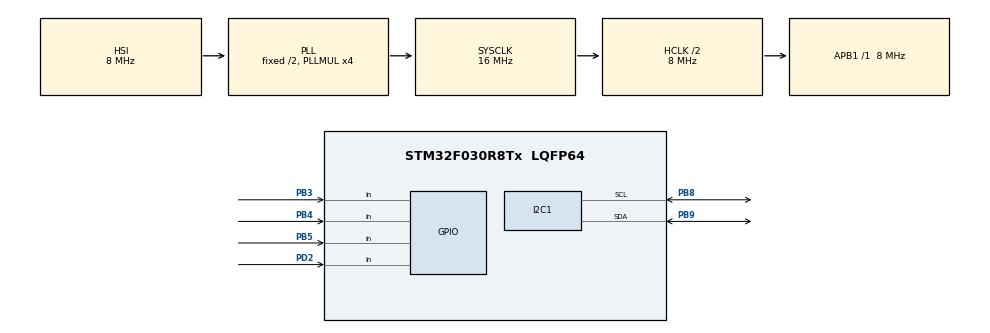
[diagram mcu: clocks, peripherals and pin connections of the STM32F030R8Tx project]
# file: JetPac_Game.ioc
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FREERTOS.Tasks01=defaultTask,0,128,StartDefaultTask,Default,NULL
Mcu.Family=STM32F0
Mcu.Name=STM32F030R8Tx
Mcu.Package=LQFP64
NVIC.TIM1_BRK_UP_TRG_COM_IRQn=true\:0\:0\:false\:false\:true\:false\:false
NVIC.TimeBase=TIM1_BRK_UP_TRG_COM_IRQn
NVIC.TimeBaseIP=TIM1
PB3.GPIO_Mode=GPIO_MODE_INPUT
PB3.GPIO_PuPd=GPIO_PULLUP
PB3.Signal=GPIO_Input
PB4.GPIO_Mode=GPIO_MODE_INPUT
PB4.GPIO_PuPd=GPIO_PULLUP
PB4.Signal=GPIO_Input
PB5.GPIO_Mode=GPIO_MODE_INPUT
PB5.GPIO_PuPd=GPIO_PULLUP
PB5.Signal=GPIO_Input
PB8.Mode=I2C
PB8.Signal=I2C1_SCL
PB9.Mode=I2C
PB9.Signal=I2C1_SDA
PD2.Signal=GPIO_Input
ProjectManager.HeapSize=0x200
ProjectManager.StackSize=0x400
ProjectManager.TargetToolchain=SW4STM32
RCC.AHBCLKDivider=RCC_SYSCLK_DIV2
RCC.AHBFreq_Value=8000000
RCC.APB1Freq_Value=8000000
RCC.APB1TimFreq_Value=8000000
RCC.HCLKFreq_Value=8000000
RCC.PLLMUL=RCC_PLL_MUL4
RCC.SYSCLKFreq_VALUE=16000000
RCC.SYSCLKSource=RCC_SYSCLKSOURCE_PLLCLK
VP_FREERTOS_VS_ENABLE.Mode=Enabled
VP_SYS_VS_tim1.Mode=TIM1
VP_TIM14_VS_ClockSourceINT.Mode=Enable_Timer
VP_TIM6_VS_ClockSourceINT.Mode=Enable_Timer
board=custom

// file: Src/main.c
/**
  ******************************************************************************
  * @file           : main.c
  * @brief          : Main program body
  ******************************************************************************
  * This notice applies to any and all portions of this file
  * that are not between comment pairs USER CODE BEGIN and
  * USER CODE END. Other portions of this file, whether
  * inserted by the user or by software development tools
  * are owned by their respective copyright owners.
  *
  * Copyright (c) 2019 STMicroelectronics International N.V.
  * All rights reserved.
  *
  * Redistribution and use in source and binary forms, with or without
  * modification, are permitted, provided that the following conditions are met:
  *
  * 1. Redistribution of source code must retain the above copyright notice,
  *    this list of conditions and the following disclaimer.
  * 2. Redistributions in binary form must reproduce the above copyright notice,
  *    this list of conditions and the following disclaimer in the documentation
  *    and/or other materials provided with the distribution.
  * 3. Neither the name of STMicroelectronics nor the names of other
  *    contributors to this software may be used to endorse or promote products
  *    derived from this software without specific written permission.
  * 4. This software, including modifications and/or derivative works of this
  *    software, must execute solely and exclusively on microcontroller or
  *    microprocessor devices manufactured by or for STMicroelectronics.
  * 5. Redistribution and use of this software other than as permitted under
  *    this license is void and will automatically terminate your rights under
  *    this license.
  *
  * THIS SOFTWARE IS PROVIDED BY STMICROELECTRONICS AND CONTRIBUTORS "AS IS"
  * AND ANY EXPRESS, IMPLIED OR STATUTORY WARRANTIES, INCLUDING, BUT NOT
  * LIMITED TO, THE IMPLIED WARRANTIES OF MERCHANTABILITY, FITNESS FOR A
  * PARTICULAR PURPOSE AND NON-INFRINGEMENT OF THIRD PARTY INTELLECTUAL PROPERTY
  * RIGHTS ARE DISCLAIMED TO THE FULLEST EXTENT PERMITTED BY LAW. IN NO EVENT
  * SHALL STMICROELECTRONICS OR CONTRIBUTORS BE LIABLE FOR ANY DIRECT, INDIRECT,
  * INCIDENTAL, SPECIAL, EXEMPLARY, OR CONSEQUENTIAL DAMAGES (INCLUDING, BUT NOT
  * LIMITED TO, PROCUREMENT OF SUBSTITUTE GOODS OR SERVICES; LOSS OF USE, DATA,
  * OR PROFITS; OR BUSINESS INTERRUPTION) HOWEVER CAUSED AND ON ANY THEORY OF
  * LIABILITY, WHETHER IN CONTRACT, STRICT LIABILITY, OR TORT (INCLUDING
  * NEGLIGENCE OR OTHERWISE) ARISING IN ANY WAY OUT OF THE USE OF THIS SOFTWARE,
  * EVEN IF ADVISED OF THE POSSIBILITY OF SUCH DAMAGE.
  *
  ******************************************************************************
  */
#include "main.h"
#include "stm32f0xx_hal.h"
#include "cmsis_os.h"

/* USER CODE BEGIN Includes */
#include "tasks.h"

//#include "CppMain.cpp"

/* USER CODE END Includes */

I2C_HandleTypeDef hi2c1;

TIM_HandleTypeDef htim6;
TIM_HandleTypeDef htim14;

osThreadId defaultTaskHandle;

/* USER CODE BEGIN PV */
/* Private variables ---------------------------------------------------------*/
osThreadId cpptask_1Handle;
osMutexId hi2c1MutexHandle;

/* USER CODE END PV */

void SystemClock_Config(void);
static void MX_GPIO_Init(void);
static void MX_TIM6_Init(void);
static void MX_TIM14_Init(void);
static void MX_I2C1_Init(void);
void StartDefaultTask(void const * argument);

/* USER CODE BEGIN PFP */
/* Private function prototypes -----------------------------------------------*/

/* USER CODE END PFP */

int main(void)
{

  /* MCU Configuration----------------------------------------------------------*/

  /* Reset of all peripherals, Initializes the Flash interface and the Systick. */
  HAL_Init();

  /* USER CODE BEGIN Init */

  //init();
  /* USER CODE END Init */

  /* Configure the system clock */
  SystemClock_Config();

  /* Initialize all configured peripherals */
  MX_GPIO_Init();
  MX_TIM6_Init();
  MX_TIM14_Init();
  MX_I2C1_Init();

  /* USER CODE BEGIN RTOS_MUTEX */
  osMutexDef(hi2c1Mutex);
  hi2c1MutexHandle = osMutexCreate(osMutex(hi2c1Mutex));
  /* USER CODE END RTOS_MUTEX */

  /* Create the thread(s) */
  /* definition and creation of defaultTask */
  //osThreadDef(defaultTask, StartDefaultTask, osPriorityNormal, 0, 128);
  //defaultTaskHandle = osThreadCreate(osThread(defaultTask), NULL);

  /* USER CODE BEGIN RTOS_THREADS */
  //osThreadDef(cpptask_1, Startcpptask_1, osPriorityNormal, 0, 128);
  xTaskCreate(cppmaintask_1,(char *)"CppMain",configMINIMAL_STACK_SIZE,NULL,3,NULL);
  //xTaskCreate(cppmaintask_2,(char *)"CppMain",configMINIMAL_STACK_SIZE,NULL,3,NULL);
  /* USER CODE END RTOS_THREADS */

  /* Start scheduler */
  osKernelStart();

  /* We should never get here as control is now taken by the scheduler */

  /* Infinite loop */
  while (1)
  {

  }

}

void SystemClock_Config(void)
{

  RCC_OscInitTypeDef RCC_OscInitStruct;
  RCC_ClkInitTypeDef RCC_ClkInitStruct;
  RCC_PeriphCLKInitTypeDef PeriphClkInit;

    /**Initializes the CPU, AHB and APB busses clocks
    */
  RCC_OscInitStruct.OscillatorType = RCC_OSCILLATORTYPE_HSI;
  RCC_OscInitStruct.HSIState = RCC_HSI_ON;
  RCC_OscInitStruct.HSICalibrationValue = 16;
  RCC_OscInitStruct.PLL.PLLState = RCC_PLL_ON;
  RCC_OscInitStruct.PLL.PLLSource = RCC_PLLSOURCE_HSI;
  RCC_OscInitStruct.PLL.PLLMUL = RCC_PLL_MUL4;
  RCC_OscInitStruct.PLL.PREDIV = RCC_PREDIV_DIV1;
  if (HAL_RCC_OscConfig(&RCC_OscInitStruct) != HAL_OK)
  {
    _Error_Handler(__FILE__, __LINE__);
  }

    /**Initializes the CPU, AHB and APB busses clocks
    */
  RCC_ClkInitStruct.ClockType = RCC_CLOCKTYPE_HCLK|RCC_CLOCKTYPE_SYSCLK
                              |RCC_CLOCKTYPE_PCLK1;
  RCC_ClkInitStruct.SYSCLKSource = RCC_SYSCLKSOURCE_PLLCLK;
  RCC_ClkInitStruct.AHBCLKDivider = RCC_SYSCLK_DIV2;
  RCC_ClkInitStruct.APB1CLKDivider = RCC_HCLK_DIV1;

  if (HAL_RCC_ClockConfig(&RCC_ClkInitStruct, FLASH_LATENCY_0) != HAL_OK)
  {
    _Error_Handler(__FILE__, __LINE__);
  }

  PeriphClkInit.PeriphClockSelection = RCC_PERIPHCLK_I2C1;
  PeriphClkInit.I2c1ClockSelection = RCC_I2C1CLKSOURCE_HSI;
  if (HAL_RCCEx_PeriphCLKConfig(&PeriphClkInit) != HAL_OK)
  {
    _Error_Handler(__FILE__, __LINE__);
  }

    /**Configure the Systick interrupt time
    */
  HAL_SYSTICK_Config(HAL_RCC_GetHCLKFreq()/1000);

    /**Configure the Systick
    */
  HAL_SYSTICK_CLKSourceConfig(SYSTICK_CLKSOURCE_HCLK);

  /* SysTick_IRQn interrupt configuration */
  HAL_NVIC_SetPriority(SysTick_IRQn, 3, 0);
}

/* I2C1 init function */
static void MX_I2C1_Init(void)
{

  hi2c1.Instance = I2C1;
  hi2c1.Init.Timing = 0x2000090E;
  hi2c1.Init.OwnAddress1 = 0;
  hi2c1.Init.AddressingMode = I2C_ADDRESSINGMODE_7BIT;
  hi2c1.Init.DualAddressMode = I2C_DUALADDRESS_DISABLE;
  hi2c1.Init.OwnAddress2 = 0;
  hi2c1.Init.OwnAddress2Masks = I2C_OA2_NOMASK;
  hi2c1.Init.GeneralCallMode = I2C_GENERALCALL_DISABLE;
  hi2c1.Init.NoStretchMode = I2C_NOSTRETCH_DISABLE;
  if (HAL_I2C_Init(&hi2c1) != HAL_OK)
  {
    _Error_Handler(__FILE__, __LINE__);
  }

    /**Configure Analogue filter
    */
  if (HAL_I2CEx_ConfigAnalogFilter(&hi2c1, I2C_ANALOGFILTER_ENABLE) != HAL_OK)
  {
    _Error_Handler(__FILE__, __LINE__);
  }

    /**Configure Digital filter
    */
  if (HAL_I2CEx_ConfigDigitalFilter(&hi2c1, 0) != HAL_OK)
  {
    _Error_Handler(__FILE__, __LINE__);
  }

}

/* TIM6 init function */
static void MX_TIM6_Init(void)
{

  htim6.Instance = TIM6;
  htim6.Init.Prescaler = 0;
  htim6.Init.CounterMode = TIM_COUNTERMODE_UP;
  htim6.Init.Period = 0;
  htim6.Init.AutoReloadPreload = TIM_AUTORELOAD_PRELOAD_DISABLE;
  if (HAL_TIM_Base_Init(&htim6) != HAL_OK)
  {
    _Error_Handler(__FILE__, __LINE__);
  }

}

/* TIM14 init function */
static void MX_TIM14_Init(void)
{

  htim14.Instance = TIM14;
  htim14.Init.Prescaler = 0;
  htim14.Init.CounterMode = TIM_COUNTERMODE_UP;
  htim14.Init.Period = 0;
  htim14.Init.ClockDivision = TIM_CLOCKDIVISION_DIV1;
  htim14.Init.AutoReloadPreload = TIM_AUTORELOAD_PRELOAD_DISABLE;
  if (HAL_TIM_Base_Init(&htim14) != HAL_OK)
  {
    _Error_Handler(__FILE__, __LINE__);
  }

}

/** Configure pins as
        * Analog
        * Input
        * Output
        * EVENT_OUT
        * EXTI
*/
static void MX_GPIO_Init(void)
{

  GPIO_InitTypeDef GPIO_InitStruct;

  /* GPIO Ports Clock Enable */
  __HAL_RCC_GPIOD_CLK_ENABLE();
  __HAL_RCC_GPIOB_CLK_ENABLE();

  /*Configure GPIO pin : PD2 */
  GPIO_InitStruct.Pin = GPIO_PIN_2;
  GPIO_InitStruct.Mode = GPIO_MODE_INPUT;
  GPIO_InitStruct.Pull = GPIO_NOPULL;
  HAL_GPIO_Init(GPIOD, &GPIO_InitStruct);

  /*Configure GPIO pins : PB3 PB4 PB5 */
  GPIO_InitStruct.Pin = GPIO_PIN_3|GPIO_PIN_4|GPIO_PIN_5;
  GPIO_InitStruct.Mode = GPIO_MODE_INPUT;
  GPIO_InitStruct.Pull = GPIO_PULLUP;
  HAL_GPIO_Init(GPIOB, &GPIO_InitStruct);

}

/* USER CODE BEGIN 4 */
//void HAL_GPIO_EXTI_Callback (uint16_t GPIO_Pin)
//{
//	if(GPIO_Pin ==  Left_Pin)
//	{
//		setB1();
//	}
//}
/* USER CODE END 4 */

/* StartDefaultTask function */
void StartDefaultTask(void const * argument)
{

  for(;;)
  {
	  osDelay(1);
  }
}

void HAL_TIM_PeriodElapsedCallback(TIM_HandleTypeDef *htim)
{
  if (htim->Instance == TIM1) {
    HAL_IncTick();
  }
}

void _Error_Handler(char *file, int line)
{
  while(1)
  {
  }
}

/************************ (C) COPYRIGHT STMicroelectronics *****END OF FILE****/
